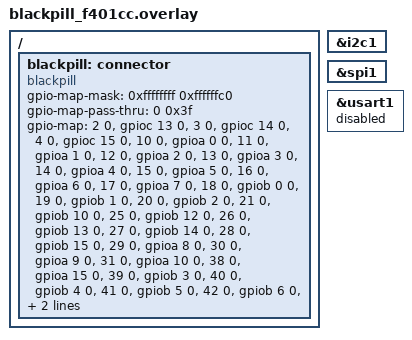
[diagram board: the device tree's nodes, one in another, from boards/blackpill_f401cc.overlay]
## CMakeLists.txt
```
cmake_minimum_required(VERSION 3.13.1)

set(CONFIG_APPLICATION_DEFINED_SYSCALL true)

set(ZEPHYR_BOARD_ALIASES "boards/aliases.cmake")
set(ZEPHYR_EXTRA_MODULES "${ZMK_EXTRA_MODULES};${CMAKE_CURRENT_SOURCE_DIR}/module;${CMAKE_CURRENT_SOURCE_DIR}/keymap-module")

# Find Zephyr. This also loads Zephyr's build system.
find_package(Zephyr REQUIRED HINTS ../zephyr)
project(zmk)

zephyr_linker_sources(SECTIONS include/linker/zmk-behaviors.ld)
zephyr_linker_sources(RODATA include/linker/zmk-events.ld)

if(CONFIG_ZMK_BEHAVIOR_LOCAL_IDS)
  zephyr_linker_sources(DATA_SECTIONS include/linker/zmk-behavior-local-id-map.ld)
endif()

zephyr_syscall_header(${APPLICATION_SOURCE_DIR}/include/drivers/behavior.h)
zephyr_syscall_header(${APPLICATION_SOURCE_DIR}/include/drivers/input_processor.h)
zephyr_syscall_header(${APPLICATION_SOURCE_DIR}/include/drivers/ext_power.h)

# Add your source file to the "app" target. This must come after
# find_package(Zephyr) which defines the target.
target_include_directories(app PRIVATE include)
add_subdirectory(src/boot)
target_sources(app PRIVATE src/stdlib.c)
target_sources(app PRIVATE src/activity.c)
target_sources(app PRIVATE src/behavior.c)
target_sources_ifdef(CONFIG_ZMK_KSCAN_SIDEBAND_BEHAVIORS app PRIVATE src/kscan_sideband_behaviors.c)
target_sources(app PRIVATE src/matrix_transform.c)
target_sources(app PRIVATE src/physical_layouts.c)
target_sources(app PRIVATE src/sensors.c)
target_sources_ifdef(CONFIG_ZMK_WPM app PRIVATE src/wpm.c)
target_sources(app PRIVATE src/event_manager.c)
target_sources_ifdef(CONFIG_ZMK_PM app PRIVATE src/pm.c)
target_sources_ifdef(CONFIG_ZMK_EXT_POWER app PRIVATE src/ext_power_generic.c)
target_sources_ifdef(CONFIG_ZMK_GPIO_KEY_WAKEUP_TRIGGER app PRIVATE src/gpio_key_wakeup_trigger.c)
target_sources(app PRIVATE src/events/activity_state_changed.c)
target_sources(app PRIVATE src/events/position_state_changed.c)
target_sources(app PRIVATE src/events/sensor_event.c)
target_sources_ifdef(CONFIG_ZMK_WPM app PRIVATE src/events/wpm_state_changed.c)
target_sources_ifdef(CONFIG_USB_DEVICE_STACK app PRIVATE src/events/usb_conn_state_changed.c)
target_sources(app PRIVATE src/behaviors/behavior_reset.c)
target_sources_ifdef(CONFIG_ZMK_EXT_POWER app PRIVATE src/behaviors/behavior_ext_power.c)
target_sources_ifdef(CONFIG_ZMK_BEHAVIOR_SOFT_OFF app PRIVATE src/behaviors/behavior_soft_off.c)
add_subdirectory_ifdef(CONFIG_ZMK_POINTING src/pointing/)
if ((NOT CONFIG_ZMK_SPLIT) OR CONFIG_ZMK_SPLIT_ROLE_CENTRAL)
  target_sources(app PRIVATE src/hid.c)
  target_sources(app PRIVATE src/behaviors/behavior_key_press.c)
  target_sources_ifdef(CONFIG_ZMK_BEHAVIOR_KEY_TOGGLE app PRIVATE src/behaviors/behavior_key_toggle.c)
  target_sources_ifdef(CONFIG_ZMK_BEHAVIOR_HOLD_TAP app PRIVATE src/behaviors/behavior_hold_tap.c)
  target_sources_ifdef(CONFIG_ZMK_BEHAVIOR_STICKY_KEY app PRIVATE src/behaviors/behavior_sticky_key.c)
  target_sources(app PRIVATE src/behaviors/behavior_caps_word.c)
  target_sources(app PRIVATE src/behaviors/behavior_key_repeat.c)
  target_sources_ifdef(CONFIG_ZMK_BEHAVIOR_MACRO app PRIVATE src/behaviors/behavior_macro.c)
  target_sources(app PRIVATE src/behaviors/behavior_momentary_layer.c)
  target_sources(app PRIVATE src/behaviors/behavior_mod_morph.c)
  target_sources(app PRIVATE src/behaviors/behavior_outputs.c)
  target_sources(app PRIVATE src/behaviors/behavior_toggle_layer.c)
  target_sources(app PRIVATE src/behaviors/behavior_to_layer.c)
  target_sources(app PRIVATE src/behaviors/behavior_transparent.c)
  target_sources(app PRIVATE src/behaviors/behavior_none.c)
  target_sources_ifdef(CONFIG_ZMK_BEHAVIOR_SENSOR_ROTATE app PRIVATE src/behaviors/behavior_sensor_rotate.c)
  target_sources_ifdef(CONFIG_ZMK_BEHAVIOR_SENSOR_ROTATE_VAR app PRIVATE src/behaviors/behavior_sensor_rotate_var.c)
  target_sources_ifdef(CONFIG_ZMK_BEHAVIOR_SENSOR_ROTATE_COMMON app PRIVATE src/behaviors/behavior_sensor_rotate_common.c)
  target_sources_ifdef(CONFIG_ZMK_BEHAVIOR_MOUSE_KEY_PRESS app PRIVATE src/behaviors/behavior_mouse_key_press.c)
  target_sources_ifdef(CONFIG_ZMK_BEHAVIOR_STUDIO_UNLOCK app PRIVATE src/behaviors/behavior_studio_unlock.c)
  target_sources_ifdef(CONFIG_ZMK_BEHAVIOR_INPUT_TWO_AXIS app PRIVATE src/behaviors/behavior_input_two_axis.c)
  target_sources(app PRIVATE src/combo.c)
  target_sources_ifdef(CONFIG_ZMK_BEHAVIOR_TAP_DANCE app PRIVATE src/behaviors/behavior_tap_dance.c)
  target_sources(app PRIVATE src/behavior_queue.c)
  target_sources(app PRIVATE src/conditional_layer.c)
  target_sources(app PRIVATE src/endpoints.c)
  target_sources(app PRIVATE src/events/endpoint_changed.c)
  target_sources(app PRIVATE src/hid_listener.c)
  target_sources(app PRIVATE src/keymap.c)
  target_sources(app PRIVATE src/events/layer_state_changed.c)
  target_sources(app PRIVATE src/events/modifiers_state_changed.c)
  target_sources(app PRIVATE src/events/keycode_state_changed.c)
  target_sources_ifdef(CONFIG_ZMK_HID_INDICATORS app PRIVATE src/hid_indicators.c)

  if (CONFIG_ZMK_BLE)
    target_sources(app PRIVATE src/events/ble_active_profile_changed.c)
    target_sources(app PRIVATE src/behaviors/behavior_bt.c)
    target_sources(app PRIVATE src/ble.c)
    target_sources(app PRIVATE src/hog.c)
  endif()
endif()

target_sources_ifdef(CONFIG_ZMK_RGB_UNDERGLOW app PRIVATE src/behaviors/behavior_rgb_underglow.c)
target_sources_ifdef(CONFIG_ZMK_BACKLIGHT app PRIVATE src/behaviors/behavior_backlight.c)

if(CONFIG_ZMK_BATTERY_REPORTING)
  target_sources(app PRIVATE src/events/battery_state_changed.c)
  target_sources(app PRIVATE src/battery.c)
  target_sources_ifdef(CONFIG_ZMK_BATTERY_REPORTING_SPLIT_PROXY app PRIVATE src/battery_reporting.c)
endif()

target_sources_ifdef(CONFIG_ZMK_HID_INDICATORS app PRIVATE src/events/hid_indicators_changed.c)
add_subdirectory_ifdef(CONFIG_ZMK_HID_INDICATORS src/indicators)

target_sources_ifdef(CONFIG_ZMK_SPLIT app PRIVATE src/events/split_peripheral_status_changed.c)
add_subdirectory_ifdef(CONFIG_ZMK_SPLIT src/split)

target_sources_ifdef(CONFIG_USB_DEVICE_STACK app PRIVATE src/usb.c)
target_sources_ifdef(CONFIG_ZMK_USB app PRIVATE src/usb_hid.c)
target_sources_ifdef(CONFIG_ZMK_RGB_UNDERGLOW app PRIVATE src/rgb_underglow.c)
target_sources_ifdef(CONFIG_ZMK_BACKLIGHT app PRIVATE src/backlight.c)
target_sources_ifdef(CONFIG_ZMK_LOW_PRIORITY_WORK_QUEUE app PRIVATE src/workqueue.c)
target_sources(app PRIVATE src/main.c)

add_subdirectory(src/display/)
add_subdirectory_ifdef(CONFIG_SETTINGS src/settings/)

if (CONFIG_ZMK_STUDIO_RPC)
  # For some reason this is failing if run from a different sub-file.
  list(APPEND CMAKE_MODULE_PATH ${ZEPHYR_BASE}/modules/nanopb)

  include(nanopb)

    # Turn off the default nanopb behavior
  set(NANOPB_GENERATE_CPP_STANDALONE OFF)

  nanopb_generate_cpp(proto_srcs proto_hdrs RELPATH ${ZEPHYR_ZMK_STUDIO_MESSAGES_MODULE_DIR}
                        ${ZEPHYR_ZMK_STUDIO_MESSAGES_MODULE_DIR}/proto/zmk/studio.proto
                        ${ZEPHYR_ZMK_STUDIO_MESSAGES_MODULE_DIR}/proto/zmk/meta.proto
                        ${ZEPHYR_ZMK_STUDIO_MESSAGES_MODULE_DIR}/proto/zmk/core.proto
                        ${ZEPHYR_ZMK_STUDIO_MESSAGES_MODULE_DIR}/proto/zmk/behaviors.proto
                        ${ZEPHYR_ZMK_STUDIO_MESSAGES_MODULE_DIR}/proto/zmk/keymap.proto
  )

  target_include_directories(app PUBLIC ${CMAKE_CURRENT_BINARY_DIR})
  target_sources(app PRIVATE ${proto_srcs} ${proto_hdrs})

  add_subdirectory(src/studio)
endif()

zephyr_cc_option(-Wfatal-errors)
```

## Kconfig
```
# Copyright (c) 2020 The ZMK Contributors
# SPDX-License-Identifier: MIT

mainmenu "ZMK Firmware"

menu "ZMK"

config ZMK_BOARD_COMPAT
    bool
    help
      Hidden symbol used to hint that a board has been specifically
      set up with various ZMK requirements in mind, e.g. settings
      storage, bootloader integration, etc.

      Failure to set this will warn users they may want to verify they
      used a ZMK variant of an upstream board, or are using a board
      properly migrated to a newer ZMK version.

menu "Basic Keyboard Setup"

config ZMK_KEYBOARD_NAME
    string "Keyboard Name"

config USB_DEVICE_PRODUCT
    default ZMK_KEYBOARD_NAME

config BT_DEVICE_NAME
    default ZMK_KEYBOARD_NAME

config USB_DEVICE_VID
    default 0x1D50

config USB_DEVICE_PID
    default 0x615E

config USB_DEVICE_MANUFACTURER
    default "ZMK Project"

config BT_DIS_PNP_VID
    default 0x1D50

config BT_DIS_PNP_PID
    default 0x615E

config BT_DIS_PNP_VID_SRC
    default 2

config BT_DIS_MODEL_NUMBER_STR
    default ZMK_KEYBOARD_NAME

config BT_DIS_MANUF_NAME_STR
    default "ZMK Project"

# Hardware specific overrides

if SOC_SERIES_NRF52X

# Default on for our usage until boards implement retained bootmode.
config NRF_STORE_REBOOT_TYPE_GPREGRET
    bool
    default y

endif # SOC_SERIES_NRF52X

menu "HID"

choice ZMK_HID_REPORT_TYPE
    prompt "HID Report Type"

config ZMK_HID_REPORT_TYPE_HKRO
    bool "#-Key Roll Over (HKRO) HID Report"
    help
      Enable # key roll over for HID report. This selection is "boot keyboard" compatible
      but limits the total number of possible keys to report as held to #.

config ZMK_HID_REPORT_TYPE_NKRO
    bool "Full N-Key Roll Over (NKRO) HID Report"
    help
      Enable full N-Key Roll Over for HID output. This selection will prevent the keyboard
      from working with some BIOS/UEFI versions that only support "boot keyboard" support.
      This option also prevents using some infrequently used higher range HID usages (notably F13-F24 and INTL1-9)
      These usages can be re enabled with ZMK_HID_KEYBOARD_NKRO_EXTENDED_REPORT.

endchoice

config ZMK_HID_KEYBOARD_NKRO_EXTENDED_REPORT
    bool "Enable extended NKRO reporting"
    depends on ZMK_HID_REPORT_TYPE_NKRO
    help
      Enables higher usage range for NKRO (F13-F24 and INTL1-9).
      Please note this is not compatible with Android currently and you will get no input


if ZMK_HID_REPORT_TYPE_HKRO

config ZMK_HID_KEYBOARD_REPORT_SIZE
    int "# Keyboard Keys Reportable"

endif # ZMK_HID_REPORT_TYPE_HKRO

config ZMK_HID_CONSUMER_REPORT_SIZE
    int "# Consumer Keys Reportable"

choice ZMK_HID_CONSUMER_REPORT_USAGES
    prompt "HID Report Type"

config ZMK_HID_CONSUMER_REPORT_USAGES_FULL
    bool "Full Consumer HID Usage Support"
    help
      Enable full Consumer usage ID values to be sent to hosts. Allows for less
      frequently used usages, but has compatibability issues with some host OSes.

config ZMK_HID_CONSUMER_REPORT_USAGES_BASIC
    bool "Basic Consumer HID Usage Support"
    help
      Enable Consumer usage ID values up to "Playback Speed - Slow" to be sent to
      hosts. Allows for broader compatibability with more host OSes.

endchoice

config ZMK_HID_INDICATORS
    bool "HID Indicators"
    help
      Enable HID indicators, used for detecting state of Caps/Scroll/Num Lock,
      Kata, and Compose.

rsource "src/indicators/Kconfig"

config ZMK_HID_SEPARATE_MOD_RELEASE_REPORT
    bool "Release Modifiers Separately"
    help
      Send a separate release event for the modifiers, to make sure the release
      of the modifier doesn't get recognized before the actual key's release event.

menu "Output Types"

config ZMK_USB
    bool "USB"
    depends on (!ZMK_SPLIT || (ZMK_SPLIT && ZMK_SPLIT_ROLE_CENTRAL))
    select USB
    select USB_DEVICE_STACK
    select USB_DEVICE_HID

config ZMK_USB_BOOT
    bool "USB Boot Protocol Support"
    depends on ZMK_USB
    select USB_HID_BOOT_PROTOCOL

config USB_DEVICE_INITIALIZE_AT_BOOT
    default n

if ZMK_USB

config USB_NUMOF_EP_WRITE_RETRIES
    default 10

config USB_HID_POLL_INTERVAL_MS
    default 1

endif # ZMK_USB

menuconfig ZMK_BLE
    bool "BLE (HID over GATT)"
    select BT
    select BT_SMP
    select BT_SMP_SC_PAIR_ONLY
    select BT_SMP_APP_PAIRING_ACCEPT
    select BT_PERIPHERAL
    select BT_DIS
    imply BT_DEVICE_NAME_DYNAMIC
    imply BT_SETTINGS if !ARCH_POSIX
    imply SETTINGS if !ARCH_POSIX
    imply ZMK_BATTERY_REPORTING if !ARCH_POSIX

if ZMK_BLE

config ZMK_BLE_EXPERIMENTAL_CONN
    bool "Experimental BLE connection changes"
    help
      Enables settings that are planned to be default in future versions of ZMK
      to improve connection stability.

config ZMK_BLE_EXPERIMENTAL_SEC
    bool "Experimental BLE security changes"
    imply BT_SMP_ALLOW_UNAUTH_OVERWRITE
    help
      Enables security settings that are planned to be officially supported in the future.

config ZMK_BLE_EXPERIMENTAL_FEATURES
    bool "Experimental BLE connection and security settings/features"
    select ZMK_BLE_EXPERIMENTAL_CONN
    select ZMK_BLE_EXPERIMENTAL_SEC
    help
      Enables experimental connection changes and security features.

config ZMK_BLE_PASSKEY_ENTRY
    bool "Require passkey entry on the keyboard to complete pairing"
    select RING_BUFFER

config BT_SMP_ALLOW_UNAUTH_OVERWRITE
    imply ZMK_BLE_PASSKEY_ENTRY

config BT_CTLR_PHY_2M
    default n if ZMK_BLE_EXPERIMENTAL_CONN

config ZMK_BLE_THREAD_STACK_SIZE
    int "BLE notify thread stack size"
    default 768

config ZMK_BLE_THREAD_PRIORITY
    int "BLE notify thread priority"
    default 5

config ZMK_BLE_KEYBOARD_REPORT_QUEUE_SIZE
    int "Max number of keyboard HID reports to queue for sending over BLE"
    default 20

config ZMK_BLE_CONSUMER_REPORT_QUEUE_SIZE
    int "Max number of consumer HID reports to queue for sending over BLE"
    default 5

config ZMK_BLE_MOUSE_REPORT_QUEUE_SIZE
    int "Max number of mouse HID reports to queue for sending over BLE"
    default 20

config ZMK_BLE_CLEAR_BONDS_ON_START
    bool "Configuration that clears all bond information from the keyboard on startup."

# HID GATT notifications sent this way are *not* picked up by Linux, and possibly others.
config BT_GATT_NOTIFY_MULTIPLE
    default n

config BT_GATT_AUTO_SEC_REQ
    default (ZMK_SPLIT_BLE && !ZMK_SPLIT_ROLE_CENTRAL)

config BT_PERIPHERAL_PREF_MIN_INT
    default 6

config BT_PERIPHERAL_PREF_MAX_INT
    default 12

config BT_PERIPHERAL_PREF_LATENCY
    default 30

config BT_PERIPHERAL_PREF_TIMEOUT
    default 400

# The device name should be 16 characters or less so it fits within the
# advertising data.
config BT_DEVICE_NAME_MAX
    default 16

endif # ZMK_BLE

endmenu # Output Types

endmenu # HID

rsource "src/split/Kconfig"

endmenu # Basic Keyboard Setup

menu "Keymaps"

config ZMK_KEYMAP_LAYER_REORDERING
    bool "Layer Reordering Support"

config ZMK_KEYMAP_SETTINGS_STORAGE
    bool "Settings Save/Load"
    depends on SETTINGS
    depends on ZMK_BEHAVIOR_LOCAL_IDS

if ZMK_KEYMAP_SETTINGS_STORAGE

config ZMK_KEYMAP_LAYER_NAME_MAX_LEN
    int "Max Layer Name Length"
    default 20

endif # ZMK_KEYMAP_SETTINGS_STORAGE

endmenu # Keymaps

rsource "src/studio/Kconfig"

menu "Display/LED Options"

rsource "src/display/Kconfig"

menuconfig ZMK_RGB_UNDERGLOW
    bool "RGB Addressable LED Underglow"
    select LED_STRIP
    select ZMK_LOW_PRIORITY_WORK_QUEUE

if ZMK_RGB_UNDERGLOW

config ZMK_RGB_UNDERGLOW_EXT_POWER
    bool "RGB underglow toggling also controls external power"

config ZMK_RGB_UNDERGLOW_BRT_MIN
    int "RGB underglow minimum brightness in percent"
    range 0 100

config ZMK_RGB_UNDERGLOW_BRT_MAX
    int "RGB underglow maximum brightness in percent"
    range ZMK_RGB_UNDERGLOW_BRT_MIN 100

config ZMK_RGB_UNDERGLOW_HUE_STEP
    int "RGB underglow hue step in degrees"
    range 0 359

config ZMK_RGB_UNDERGLOW_SAT_STEP
    int "RGB underglow saturation step in percent"
    range 0 100

config ZMK_RGB_UNDERGLOW_BRT_STEP
    int "RGB underglow brightness step in percent"
    range 0 100

config ZMK_RGB_UNDERGLOW_HUE_START
    int "RGB underglow start hue value in degrees"
    range 0 359

config ZMK_RGB_UNDERGLOW_SAT_START
    int "RGB underglow start saturations value in percent"
    range 0 100

config ZMK_RGB_UNDERGLOW_BRT_START
    int "RGB underglow start brightness value in percent"
    range ZMK_RGB_UNDERGLOW_BRT_MIN ZMK_RGB_UNDERGLOW_BRT_MAX

config ZMK_RGB_UNDERGLOW_SPD_START
    int "RGB underglow start animation speed value"
    range 1 5

config ZMK_RGB_UNDERGLOW_EFF_START
    int "RGB underglow start effect int value related to the effect enum list"
    range 0 3

config ZMK_RGB_UNDERGLOW_ON_START
    bool "RGB underglow starts on by default"

config ZMK_RGB_UNDERGLOW_AUTO_OFF_IDLE
    bool "Turn off RGB underglow when keyboard goes into idle state"

config ZMK_RGB_UNDERGLOW_AUTO_OFF_USB
    bool "Turn off RGB underglow when USB is disconnected"
    depends on USB_DEVICE_STACK

endif # ZMK_RGB_UNDERGLOW

menuconfig ZMK_BACKLIGHT
    bool "LED backlight"
    select LED

if ZMK_BACKLIGHT

config ZMK_BACKLIGHT_BRT_STEP
    int "Brightness step in percent"
    range 1 100

config ZMK_BACKLIGHT_BRT_START
    int "Default brightness in percent"
    range 1 100

config ZMK_BACKLIGHT_ON_START
    bool "Default backlight state"

config ZMK_BACKLIGHT_AUTO_OFF_IDLE
    bool "Turn off backlight when keyboard goes into idle state"

config ZMK_BACKLIGHT_AUTO_OFF_USB
    bool "Turn off backlight when USB is disconnected"

endif # ZMK_BACKLIGHT

endmenu # Display/LED Options

rsource "src/pointing/Kconfig"

menu "Power Management"

config ZMK_BATTERY_REPORTING
    bool "Battery level detection/reporting"
    select SENSOR
    select ZMK_LOW_PRIORITY_WORK_QUEUE

if ZMK_BATTERY_REPORTING

choice ZMK_BATTERY_REPORTING_FETCH_MODE
    prompt "Battery Reporting Fetch Mode"

config ZMK_BATTERY_REPORTING_FETCH_MODE_STATE_OF_CHARGE
    bool "State of charge"

config ZMK_BATTERY_REPORTING_FETCH_MODE_LITHIUM_VOLTAGE
    bool "Lithium Voltage"

endchoice

config ZMK_BATTERY_REPORTING_BLE
    bool "Report Battery Level over BLE Battery Service"
    default y
    depends on ZMK_BLE
    select BT_BAS if (!ZMK_SPLIT || (ZMK_SPLIT && !ZMK_SPLIT_ROLE_CENTRAL))

config ZMK_BATTERY_REPORTING_USB
    bool "Report Battery Level over USB HID"
    depends on ZMK_USB

config ZMK_BATTERY_CHARGE_STATUS
    bool "Report whether the battery is charging"
    default y
    depends on DT_HAS_ZMK_BATTERY_CHARGE_STATUS_ENABLED
    select BT_BAS_BLS if BT_BAS
    help
      Reads the status output of the board's battery charger to report whether
      the battery is charging, using the zmk,battery-charge-status devicetree
      node. Without such a node there is no way to know, and the charge state
      is reported as unknown.

if ZMK_SPLIT_ROLE_CENTRAL

config ZMK_BATTERY_REPORTING_SPLIT_FETCHING
    bool "Fetch Peripheral Battery Level Info"
    help
      Adds internal support for fetching the battery levels from peripherals
      and generating events in the ZMK eventing system.

config ZMK_BATTERY_PROXY
    bool "Proxy Battery Level Info"
    default y if ZMK_SPLIT_BLE_CENTRAL_BATTERY_LEVEL_PROXY
    help
      Adds support for reporting the battery levels of connected split
      peripherals through additional Battery Level services.

config ZMK_BATTERY_PROXY_REPORT_LOWEST_CHARGE
    bool "Report the lowest charge of all batteries"
    depends on ZMK_BATTERY_PROXY
    default y
    help
      Report the lowest charge as the first battery level to hosts.

endif # ZMK_SPLIT_ROLE_CENTRAL

endif # ZMK_BATTERY_REPORTING

config ZMK_IDLE_TIMEOUT
    int "Milliseconds of inactivity before entering idle state (OLED shutoff, etc)"
    default 30000

config ZMK_SLEEP
    bool "Enable deep sleep support"
    depends on HAS_POWEROFF
    select POWEROFF
    select ZMK_PM_DEVICE_SUSPEND_RESUME
    imply USB

if ZMK_SLEEP

config PM_DEVICE
    default y

config ZMK_IDLE_SLEEP_TIMEOUT
    int "Milliseconds of inactivity before entering deep sleep"
    default 900000

endif # ZMK_SLEEP

config ZMK_EXT_POWER
    bool "Enable support to control external power output"

config ZMK_PM
    bool

config ZMK_PM_DEVICE_SUSPEND_RESUME
    bool
    select ZMK_PM

config ZMK_PM_SOFT_OFF
    bool "Soft-off support"
    depends on HAS_POWEROFF
    select ZMK_PM
    select PM_DEVICE
    select ZMK_PM_DEVICE_SUSPEND_RESUME
    select POWEROFF

config ZMK_GPIO_KEY_WAKEUP_TRIGGER
    bool "Hardware supported wakeup (GPIO)"
    default y
    depends on DT_HAS_ZMK_GPIO_KEY_WAKEUP_TRIGGER_ENABLED && ZMK_PM_SOFT_OFF

# Power Management
endmenu

menu "Combo options"

config ZMK_COMBO_MAX_PRESSED_COMBOS
    int "Maximum number of currently pressed combos"
    default 4

config ZMK_COMBO_MAX_COMBOS_PER_KEY
    int "Deprecated: Max combos per key"
    default 0
    help
      Deprecated: Storage for combos is now determined automatically

config ZMK_COMBO_MAX_KEYS_PER_COMBO
    int "Deprecated: Max keys per combo"
    default 0
    help
       Deprecated: This is now auto-calculated based on `key-positions` in devicetree

# Combo options
endmenu

menu "Behavior Options"

config ZMK_BEHAVIORS_QUEUE_SIZE
    int "Maximum number of behaviors to allow queueing from a macro or other complex behavior"
    default 64

rsource "Kconfig.behaviors"

config ZMK_MACRO_DEFAULT_WAIT_MS
    int "Default time to wait (in milliseconds) before triggering the next behavior in macros"
    default 15

config ZMK_MACRO_DEFAULT_TAP_MS
    int "Default time to wait (in milliseconds) between the press and release events of a tapped behavior in macros"
    default 30

endmenu

menu "Advanced"

rsource "src/boot/Kconfig"

menu "Initialization Priorities"

if USB_DEVICE_STACK

config ZMK_USB_INIT_PRIORITY
    int "USB Init Priority"
    default 96

config ZMK_USB_HID_INIT_PRIORITY
    int "USB HID Init Priority"
    default 95

endif # USB

if ZMK_BLE || ZMK_SPLIT_BLE

config ZMK_BLE_INIT_PRIORITY
    int "BLE Init Priority"
    default 50

endif # ZMK_BLE || ZMK_SPLIT_BLE

endmenu # Initialization Priorities

config ZMK_PHYSICAL_LAYOUT_KEY_ROTATION
    bool "Support rotation of keys in physical layouts"
    default y

menuconfig ZMK_KSCAN
    bool "ZMK KScan Integration"
    default y
    select KSCAN

if ZMK_KSCAN

config ZMK_KSCAN_EVENT_QUEUE_SIZE
    int "Size of the event queue for KSCAN events to buffer events"
    default 4

endif # ZMK_KSCAN

config ZMK_KSCAN_SIDEBAND_BEHAVIORS
    bool
    default y
    depends on DT_HAS_ZMK_KSCAN_SIDEBAND_BEHAVIORS_ENABLED
    select KSCAN

if ZMK_KSCAN_SIDEBAND_BEHAVIORS

config ZMK_KSCAN_SIDEBAND_BEHAVIORS_INIT_PRIORITY
    int "Keyboard scan sideband behaviors driver init priority"
    # The default kscan init priority is 90, so be sure we are initialized later.
    default 95

endif # ZMK_KSCAN_SIDEBAND_BEHAVIORS

menu "Logging"

config ZMK_LOGGING_MINIMAL
    bool "Suppress all ZMK debug log messages"
    default false

if !ZMK_LOGGING_MINIMAL

config ZMK_LOG_LEVEL
    default 4

endif

config ZMK_USB_LOGGING
    bool "Enable USB CDC ACM logging to help debug"
    select LOG
    select USB
    select USB_DEVICE_STACK
    select USB_CDC_ACM
    select SERIAL
    select CONSOLE
    select UART_INTERRUPT_DRIVEN
    select UART_LINE_CTRL
    select UART_CONSOLE
    select USB_UART_CONSOLE

if ZMK_USB_LOGGING

choice USB_CDC_ACM_LOG_LEVEL_CHOICE
    default USB_CDC_ACM_LOG_LEVEL_OFF
endchoice

choice USB_DRIVER_LOG_LEVEL_CHOICE
    default USB_DRIVER_LOG_LEVEL_OFF
endchoice

# We do this to avoid log loop where logging to USB generates more log messages.

config USB_CDC_ACM_RINGBUF_SIZE
    default 1024

config LOG_PROCESS_THREAD_STARTUP_DELAY_MS
    default 1000

endif # ZMK_USB_LOGGING

config ZMK_RTT_LOGGING
    bool "Enable RTT logging to help debug"
    select LOG
    select DEBUG
    select ASSERT
    select USE_SEGGER_RTT
    select CONSOLE
    select RTT_CONSOLE

if ZMK_RTT_LOGGING

config SEGGER_RTT_BUFFER_SIZE_UP
    default 8192

endif # ZMK_RTT_LOGGING

if ZMK_USB_LOGGING || ZMK_RTT_LOGGING

config LOG_BUFFER_SIZE
    default 8192

config LOG_PROCESS_THREAD_SLEEP_MS
    default 100

endif # ZMK_USB_LOGGING || ZMK_RTT_LOGGING

endmenu # Logging

if SETTINGS

config ZMK_SETTINGS_RESET_ON_START
    bool "Delete all persistent settings when the keyboard boots"

if ZMK_SETTINGS_RESET_ON_START

config ZMK_SETTINGS_RESET_ON_START_INIT_PRIORITY
    int "Settings Reset ON Start Initialization Priority"
    default 60
    help
      Initialization priority for the settings reset on start. Must be lower priority/
      higher value than FLASH_INIT_PRIORITY if using the NVS/Flash settings backend.

endif # ZMK_SETTINGS_RESET_ON_START

config ZMK_SETTINGS_SAVE_DEBOUNCE
    int "Milliseconds to debounce settings saves"
    default 60000

endif # SETTINGS

config ZMK_BATTERY_REPORT_INTERVAL
    depends on ZMK_BATTERY_REPORTING
    int "Battery level report interval in seconds"

config ZMK_LOW_PRIORITY_WORK_QUEUE
    bool "Work queue for low priority items"

if ZMK_LOW_PRIORITY_WORK_QUEUE

config ZMK_LOW_PRIORITY_THREAD_STACK_SIZE
    int "Low priority thread stack size"
    default 768

config ZMK_LOW_PRIORITY_THREAD_PRIORITY
    int "Low priority thread priority"
    default 10

endif # ZMK_LOW_PRIORITY_WORK_QUEUE

endmenu # Advanced

endmenu # ZMK

if SOC_FAMILY_NORDIC_NRF

config NRF_SOC_VALIDATE_HEADERS_DISABLED
    default y

endif

config KERNEL_BIN_NAME
    default "zmk"

config REBOOT
    default y

config USB_DEVICE_STACK
    default y if HAS_HW_NRF_USBD

config FPU
    default CPU_HAS_FPU

config ZMK_WPM
    bool "Calculate WPM"

config ZMK_KEYMAP_SENSORS
    bool "Enable Keymap Sensors support"
    default y
    depends on DT_HAS_ZMK_KEYMAP_SENSORS_ENABLED
    select SENSOR

if ZMK_KEYMAP_SENSORS

config ZMK_KEYMAP_SENSORS_DEFAULT_TRIGGERS_PER_ROTATION
    int "Default triggers per rotation"
    help
      Unless overridden for a sensor in the board/shield/devicetree, this value
      determines how many times to trigger the bound behavior per full rotation.
      For tactile encoders with detents, this usually should match the number of
      detents per rotation of the encoder.
    default 20

endif # ZMK_KEYMAP_SENSORS

module = ZMK
module-str = zmk
source "subsys/logging/Kconfig.template.log_config"

# This loads ZMK's internal board and shield Kconfigs
rsource "boards/Kconfig"
rsource "boards/shields/*/Kconfig.defconfig"
rsource "boards/shields/*/Kconfig.shield"

# This loads custom shields defconfigs (from BOARD_ROOT)
# Duplicated from Kconfig.zephyr
osource "$(KCONFIG_BINARY_DIR)/Kconfig.shield.defconfig"

# This loads board and shield Kconfigs found under zmk-config/config/
osource "$(ZMK_CONFIG)/boards/shields/*/Kconfig.defconfig"
osource "$(ZMK_CONFIG)/boards/shields/*/Kconfig.shield"

# This loads ZMK's sensible defaults
rsource "Kconfig.defaults"

source "Kconfig.zephyr"
```

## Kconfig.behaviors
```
# Copyright (c) 2023 The ZMK Contributors
# SPDX-License-Identifier: MIT

config ZMK_BEHAVIOR_METADATA
    bool "Metadata"
    help
      Enabling this option adds APIs for documenting and fetching
      metadata describing a behaviors name, and supported parameters.

config ZMK_BEHAVIOR_LOCAL_IDS
    bool "Local IDs"

if ZMK_BEHAVIOR_LOCAL_IDS

config ZMK_BEHAVIOR_LOCAL_IDS_IN_BINDINGS
    bool "Track in behavior bindings"

choice ZMK_BEHAVIOR_LOCAL_ID_TYPE
    prompt "Local ID Type"

config ZMK_BEHAVIOR_LOCAL_ID_TYPE_SETTINGS_TABLE
    bool "Settings Table"
    depends on SETTINGS
    select ZMK_BEHAVIOR_LOCAL_IDS_IN_BINDINGS
    help
      Use persistent entries in the settings subsystem to identify
      behaviors by local ID, which uses the device name to generate
      a new settings entry tying a presistant local ID to that name.
      This guarantees stable, colllision-free local IDs at the expense
      of settings storage used.

config ZMK_BEHAVIOR_LOCAL_ID_TYPE_CRC16
    bool "CRC16 Hash"
    select CRC
    help
      Use the CRC16-ANSI hash of behavior device names to generate
      stable behavior local IDs. This saves on settings storage at
      the expense of (highly unlikely) risk of collisions.

endchoice

endif


config ZMK_BEHAVIOR_HOLD_TAP
    bool
    default y
    depends on DT_HAS_ZMK_BEHAVIOR_HOLD_TAP_ENABLED

if ZMK_BEHAVIOR_HOLD_TAP

config ZMK_BEHAVIOR_HOLD_TAP_MAX_HELD
    int "Hold Tap Max Held"
    help
      Max number of simultaneously held hold-taps

config ZMK_BEHAVIOR_HOLD_TAP_MAX_CAPTURED_EVENTS
    int "Hold Tap Max Captured Events"
    help
      Max number of captured system events while waiting to resolve hold taps

endif

config ZMK_BEHAVIOR_KEY_TOGGLE
    bool
    default y
    depends on DT_HAS_ZMK_BEHAVIOR_KEY_TOGGLE_ENABLED

config ZMK_BEHAVIOR_MOUSE_KEY_PRESS
    bool
    default y
    depends on DT_HAS_ZMK_BEHAVIOR_MOUSE_KEY_PRESS_ENABLED && ZMK_POINTING

config ZMK_BEHAVIOR_STICKY_KEY
    bool
    default y
    depends on DT_HAS_ZMK_BEHAVIOR_STICKY_KEY_ENABLED

if ZMK_BEHAVIOR_STICKY_KEY

config ZMK_BEHAVIOR_STICKY_KEY_MAX_HELD
    int "Sticky Key Max Held"
    help
      Max number of simultaneously held sticky keys

endif

config ZMK_BEHAVIOR_SOFT_OFF
    bool
    default y
    depends on DT_HAS_ZMK_BEHAVIOR_SOFT_OFF_ENABLED && ZMK_PM_SOFT_OFF


config ZMK_BEHAVIOR_TAP_DANCE
    bool
    default y
    depends on DT_HAS_ZMK_BEHAVIOR_TAP_DANCE_ENABLED

if ZMK_BEHAVIOR_TAP_DANCE

config ZMK_BEHAVIOR_TAP_DANCE_MAX_HELD
    int "Tap-Dance Max Held"
    help
      Max number of simultaneously held taps-dances

endif

config ZMK_BEHAVIOR_INPUT_TWO_AXIS
    bool
    default y
    depends on DT_HAS_ZMK_BEHAVIOR_INPUT_TWO_AXIS_ENABLED && ZMK_POINTING

config ZMK_BEHAVIOR_SENSOR_ROTATE_COMMON
    bool

config ZMK_BEHAVIOR_SENSOR_ROTATE
    bool
    default y
    depends on DT_HAS_ZMK_BEHAVIOR_SENSOR_ROTATE_ENABLED
    select ZMK_BEHAVIOR_SENSOR_ROTATE_COMMON

config ZMK_BEHAVIOR_SENSOR_ROTATE_VAR
    bool
    default y
    depends on DT_HAS_ZMK_BEHAVIOR_SENSOR_ROTATE_VAR_ENABLED
    select ZMK_BEHAVIOR_SENSOR_ROTATE_COMMON

config ZMK_BEHAVIOR_STUDIO_UNLOCK
    bool
    default y
    depends on DT_HAS_ZMK_BEHAVIOR_STUDIO_UNLOCK_ENABLED && ZMK_STUDIO

config ZMK_BEHAVIOR_MACRO
    bool
    default y
    depends on DT_HAS_ZMK_BEHAVIOR_MACRO_ENABLED || DT_HAS_ZMK_BEHAVIOR_MACRO_ONE_PARAM_ENABLED || DT_HAS_ZMK_BEHAVIOR_MACRO_TWO_PARAM_ENABLED

config ZMK_BEHAVIOR_TRI_STATE
    bool
    default y
    depends on DT_HAS_ZMK_BEHAVIOR_TRI_STATE_ENABLED
```

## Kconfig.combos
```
# Copyright (c) 2020 The ZMK Contributors
# SPDX-License-Identifier: MIT

menuconfig ZMK_COMBOS
    bool "Combos"
    default y
    depends on DT_HAS_ZMK_COMBOS_ENABLED

if ZMK_COMBOS

config ZMK_COMBO_MAX_PRESSED_COMBOS
    int "Maximum number of currently pressed combos"
    default 4

config ZMK_COMBO_MAX_COMBOS_PER_KEY
    int "Deprecated: Max combos per key"
    default 0
    help
      Deprecated: Storage for combos is now determined automatically

config ZMK_COMBO_MAX_KEYS_PER_COMBO
    int "Deprecated: Max keys per combo"
    default 0
    help
       Deprecated: This is now auto-calculated based on `key-positions` in devicetree

config ZMK_COMBOS_RUNTIME
    bool "Runtime combo updates"

if ZMK_COMBOS_RUNTIME

config ZMK_COMBOS_RUNTIME_SETTINGS_STORAGE
    bool "Save/restore runtime combos using settings"
    default y
    depends on SETTINGS

config ZMK_COMBOS_RUNTIME_SHELL_CMD
    bool "Combos shell command"
    default y
    depends on SHELL

endif

endif
```

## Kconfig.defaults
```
# Copyright (c) 2024 The ZMK Contributors
# SPDX-License-Identifier: MIT

config SYSTEM_WORKQUEUE_STACK_SIZE
    default 3072 if ZMK_DISPLAY
    default 2048

# Basic
config BT_DEVICE_APPEARANCE
    default 961

# HID
if ZMK_HID_REPORT_TYPE_HKRO

config ZMK_HID_KEYBOARD_REPORT_SIZE
    default 6

endif

config ZMK_HID_CONSUMER_REPORT_SIZE
    default 6

# Behaviors

if ZMK_BEHAVIOR_HOLD_TAP

config ZMK_BEHAVIOR_HOLD_TAP_MAX_HELD
    default 10

config ZMK_BEHAVIOR_HOLD_TAP_MAX_CAPTURED_EVENTS
    default 40

endif

if ZMK_BEHAVIOR_STICKY_KEY

config ZMK_BEHAVIOR_STICKY_KEY_MAX_HELD
    default 10

endif

if ZMK_BEHAVIOR_TAP_DANCE

config ZMK_BEHAVIOR_TAP_DANCE_MAX_HELD
    default 10

endif

# Underglow
if ZMK_RGB_UNDERGLOW

# This default value cuts down on tons of excess .conf files, if you're using GPIO, manually disable this
config SPI
    default y

config ZMK_RGB_UNDERGLOW_EXT_POWER
    default y

config ZMK_RGB_UNDERGLOW_BRT_MIN
    default 0

config ZMK_RGB_UNDERGLOW_BRT_MAX
    default 100

config ZMK_RGB_UNDERGLOW_HUE_STEP
    default 10

config ZMK_RGB_UNDERGLOW_SAT_STEP
    default 10

config ZMK_RGB_UNDERGLOW_BRT_STEP
    default 10

config ZMK_RGB_UNDERGLOW_HUE_START
    default 0

config ZMK_RGB_UNDERGLOW_SAT_START
    default 100

config ZMK_RGB_UNDERGLOW_BRT_START
    default ZMK_RGB_UNDERGLOW_BRT_MAX

config ZMK_RGB_UNDERGLOW_SPD_START
    default 3

config ZMK_RGB_UNDERGLOW_EFF_START
    default 0

config ZMK_RGB_UNDERGLOW_ON_START
    default y

endif # ZMK_RGB_UNDERGLOW

# Backlight
if ZMK_BACKLIGHT

config ZMK_BACKLIGHT_BRT_STEP
    default 20

config ZMK_BACKLIGHT_BRT_START
    default 40

config ZMK_BACKLIGHT_ON_START
    default y

endif # ZMK_BACKLIGHT

# LED matrix
if ZMK_LED_MATRIX

config ZMK_LED_MATRIX_BRT_STEP
    default 10

config ZMK_LED_MATRIX_BRT_START
    default 60

config ZMK_LED_MATRIX_PROFILE_START
    default 0

config ZMK_LED_MATRIX_SPD_LEVELS
    default 7

config ZMK_LED_MATRIX_SPD_START
    default 4 if ZMK_LED_MATRIX_SPD_LEVELS >= 4
    default ZMK_LED_MATRIX_SPD_LEVELS

config ZMK_LED_MATRIX_ON_START
    default y

config ZMK_LED_MATRIX_IDLE_STATUS_WAKE_TIMEOUT
    default 1800000

endif # ZMK_LED_MATRIX

# Ext_power
config ZMK_EXT_POWER
    default y

# Battery
config ZMK_BATTERY_REPORT_INTERVAL
    default 60

# Imports
rsource "src/boot/Kconfig.defaults"
rsource "src/split/Kconfig.defaults"
```

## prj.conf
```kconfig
CONFIG_APPLICATION_DEFINED_SYSCALL=y

CONFIG_BT_SMP_SC_PAIR_ONLY=n
```

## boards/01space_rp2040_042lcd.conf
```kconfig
CONFIG_ZMK_DISPLAY=y
CONFIG_LV_FONT_UNSCII_8=n
CONFIG_ZMK_USB=y
CONFIG_I2C=y
CONFIG_I2C_DW=y
CONFIG_LV_Z_VDB_SIZE=50
```

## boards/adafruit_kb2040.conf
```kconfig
CONFIG_CONSOLE=n
CONFIG_SERIAL=n
CONFIG_UART_CONSOLE=n
CONFIG_ZMK_USB=y

CONFIG_RETAINED_MEM=y
CONFIG_RETENTION=y
CONFIG_RETENTION_BOOT_MODE=y
```

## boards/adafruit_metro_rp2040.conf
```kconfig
CONFIG_CONSOLE=n
CONFIG_SERIAL=n
CONFIG_UART_CONSOLE=n
CONFIG_ZMK_USB=y

CONFIG_MPU_ALLOW_FLASH_WRITE=y
CONFIG_NVS=y
CONFIG_SETTINGS_NVS=y
CONFIG_FLASH=y
CONFIG_FLASH_PAGE_LAYOUT=y
CONFIG_FLASH_MAP=y
```

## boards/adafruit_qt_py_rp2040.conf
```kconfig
CONFIG_CONSOLE=n
CONFIG_SERIAL=n
CONFIG_UART_CONSOLE=n
CONFIG_ZMK_USB=y

CONFIG_RETAINED_MEM=y
CONFIG_RETENTION=y
CONFIG_RETENTION_BOOT_MODE=y
```

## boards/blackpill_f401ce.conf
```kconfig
CONFIG_CONSOLE=n
CONFIG_SERIAL=n
CONFIG_UART_CONSOLE=n
CONFIG_UART_INTERRUPT_DRIVEN=n
CONFIG_ZMK_USB=y
CONFIG_ZMK_KSCAN_MATRIX_POLLING=y
```

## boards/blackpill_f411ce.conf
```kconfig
CONFIG_CONSOLE=n
CONFIG_SERIAL=n
CONFIG_UART_CONSOLE=n
CONFIG_UART_INTERRUPT_DRIVEN=n
CONFIG_ZMK_USB=y
CONFIG_ZMK_BLE=n
CONFIG_ZMK_KSCAN_MATRIX_POLLING=y
```

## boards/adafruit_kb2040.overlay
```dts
/*
 * Copyright (c) 2023 The ZMK Contributors
 *
 * SPDX-License-Identifier: MIT
 */

#include <common/rp2-boot-mode-retention.dtsi>

&pro_micro_serial { status = "disabled"; };
```

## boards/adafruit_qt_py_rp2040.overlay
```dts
/*
 * Copyright (c) 2023 The ZMK Contributors
 *
 * SPDX-License-Identifier: MIT
 */

#include <common/rp2-boot-mode-retention.dtsi>

&xiao_serial { status = "disabled"; };
```

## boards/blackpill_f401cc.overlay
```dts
/*
 * Copyright (c) 2024 The ZMK Contributors
 *
 * SPDX-License-Identifier: MIT
 */

/ {
    blackpill: connector {
        compatible = "blackpill";
        #gpio-cells = <2>;
        gpio-map-mask = <0xffffffff 0xffffffc0>;
        gpio-map-pass-thru = <0 0x3f>;
        gpio-map
            = <2  0 &gpioc 13 0>    /* PC13 */
            , <3  0 &gpioc 14 0>    /* PC14 */
            , <4  0 &gpioc 15 0>    /* PC15 */
            , <10 0 &gpioa 0  0>    /* PA0  */
            , <11 0 &gpioa 1  0>    /* PA1  */
            , <12 0 &gpioa 2  0>    /* PA2  */
            , <13 0 &gpioa 3  0>    /* PA3  */
            , <14 0 &gpioa 4  0>    /* PA4  */
            , <15 0 &gpioa 5  0>    /* PA5  */
            , <16 0 &gpioa 6  0>    /* PA6  */
            , <17 0 &gpioa 7  0>    /* PA7  */
            , <18 0 &gpiob 0  0>    /* PB0  */
            , <19 0 &gpiob 1  0>    /* PB1  */
            , <20 0 &gpiob 2  0>    /* PB2  */
            , <21 0 &gpiob 10 0>    /* PB10 */
            , <25 0 &gpiob 12 0>    /* PB12 */
            , <26 0 &gpiob 13 0>    /* PB13 */
            , <27 0 &gpiob 14 0>    /* PB14 */
            , <28 0 &gpiob 15 0>    /* PB15 */
            , <29 0 &gpioa 8  0>    /* PA8  */
            , <30 0 &gpioa 9  0>    /* PA9  */
            , <31 0 &gpioa 10 0>    /* PA10 */
            , <38 0 &gpioa 15 0>    /* PA15 */
            , <39 0 &gpiob 3  0>    /* PB3  */
            , <40 0 &gpiob 4  0>    /* PB4  */
            , <41 0 &gpiob 5  0>    /* PB5  */
            , <42 0 &gpiob 6  0>    /* PB6  */
            , <43 0 &gpiob 7  0>    /* PB7  */
            , <45 0 &gpiob 8  0>    /* PB8  */
            , <46 0 &gpiob 9  0>    /* PB9  */
            ;
    };
};

blackpill_i2c: &i2c1 {};
blackpill_spi: &spi1 {};
blackpill_serial: &usart1 {};

&blackpill_serial { status = "disabled"; };
```

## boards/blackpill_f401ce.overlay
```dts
/*
 * Copyright (c) 2022 The ZMK Contributors
 *
 * SPDX-License-Identifier: MIT
 */


/ {
    blackpill: connector {
        compatible = "blackpill";
        #gpio-cells = <2>;
        gpio-map-mask = <0xffffffff 0xffffffc0>;
        gpio-map-pass-thru = <0 0x3f>;
        gpio-map
            = <2  0 &gpioc 13 0>    /* PC13 */
            , <3  0 &gpioc 14 0>    /* PC14 */
            , <4  0 &gpioc 15 0>    /* PC15 */
            , <10 0 &gpioa 0  0>    /* PA0  */
            , <11 0 &gpioa 1  0>    /* PA1  */
            , <12 0 &gpioa 2  0>    /* PA2  */
            , <13 0 &gpioa 3  0>    /* PA3  */
            , <14 0 &gpioa 4  0>    /* PA4  */
            , <15 0 &gpioa 5  0>    /* PA5  */
            , <16 0 &gpioa 6  0>    /* PA6  */
            , <17 0 &gpioa 7  0>    /* PA7  */
            , <18 0 &gpiob 0  0>    /* PB0  */
            , <19 0 &gpiob 1  0>    /* PB1  */
            , <20 0 &gpiob 2  0>    /* PB2  */
            , <21 0 &gpiob 10 0>    /* PB10 */
            , <25 0 &gpiob 12 0>    /* PB12 */
            , <26 0 &gpiob 13 0>    /* PB13 */
            , <27 0 &gpiob 14 0>    /* PB14 */
            , <28 0 &gpiob 15 0>    /* PB15 */
            , <29 0 &gpioa 8  0>    /* PA8  */
            , <30 0 &gpioa 9  0>    /* PA9  */
            , <31 0 &gpioa 10 0>    /* PA10 */
            , <38 0 &gpioa 15 0>    /* PA15 */
            , <39 0 &gpiob 3  0>    /* PB3  */
            , <40 0 &gpiob 4  0>    /* PB4  */
            , <41 0 &gpiob 5  0>    /* PB5  */
            , <42 0 &gpiob 6  0>    /* PB6  */
            , <43 0 &gpiob 7  0>    /* PB7  */
            , <45 0 &gpiob 8  0>    /* PB8  */
            , <46 0 &gpiob 9  0>    /* PB9  */
            ;
    };
};

blackpill_i2c: &i2c1 {};
blackpill_spi: &spi1 {};
blackpill_serial: &usart1 {};

&blackpill_serial { status = "disabled"; };
```

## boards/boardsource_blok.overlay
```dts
/*
 * Copyright (c) 2023 The ZMK Contributors
 *
 * SPDX-License-Identifier: MIT
 */

#include "usb_console.dtsi"

&pro_micro_serial { status = "disabled"; };
```

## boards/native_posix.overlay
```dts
#include <behaviors.dtsi>
#include <dt-bindings/zmk/keys.h>
#include <dt-bindings/zmk/kscan_mock.h>

/ {
    chosen {
        zmk,kscan = &kscan;
    };

    kscan: kscan {
        compatible = "zmk,kscan-mock";

        rows = <2>;
        columns = <2>;
        exit-after;
    };
};
```

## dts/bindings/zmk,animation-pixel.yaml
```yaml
# Copyright (c) 2020, The ZMK Contributors
# SPDX-License-Identifier: MIT

description: Pixel configuration

compatible: "zmk,animation-pixel"

pixel-cells:
  - position_x
  - position_y
```

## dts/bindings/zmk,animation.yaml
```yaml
# Copyright (c) 2020, The ZMK Contributors
# SPDX-License-Identifier: MIT

description: Global animation configuration

compatible: "zmk,animation"

properties:
  drivers:
    type: phandles
    required: true
    description: |
      This array should contain all driver devices responsible for illuminating animated LEDs.
      The devices must implement Zephyr's LED Strip Interface.

  chain-lengths:
    type: array
    required: true
    description: |
      This field contains the number of LEDs controlled by each driver device.

  pixels:
    type: phandle-array
    required: true
    description: |
      This field contains the pixel configuration for the entire board.
      The order of this array determines in what order pixels are sent to the driver device API.
      If multiple driving devices are used, their chain-length property determines the size of the buffer for each device.

  key-pixels:
    type: array
    description: |
      Use this field to specify the pixel index corresponding to each key
      following the order used in your keymap.
      When left unspecified, the driver assumes that for every key, the pixel has a matching id.
      So for N keys, the first N pixels are exactly in the same order as keys in your keymap.
```

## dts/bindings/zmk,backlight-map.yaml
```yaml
description: |
  Allows defining a keymap composed of multiple layers

compatible: "zmk,backlight-map"

properties:
  led-channels:
    type: phandle-array
    required: true
```

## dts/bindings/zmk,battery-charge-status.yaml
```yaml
# Copyright (c) 2026 The ZMK Contributors
# SPDX-License-Identifier: MIT

description: |
  Reports whether the battery is charging, by reading the status output(s) of a
  battery charger IC.

  The charger ICs used on wireless keyboards expose one or two open drain status
  pins that are pulled low to signal a state, so they are normally described
  with GPIO_ACTIVE_LOW, and need a pull up if the board does not have one.

  A charger with a single status pin, such as the MCP73831, cannot distinguish
  "charge complete" from "no power applied":

      charge_status {
          compatible = "zmk,battery-charge-status";
          charging-gpios = <&gpio0 5 (GPIO_ACTIVE_LOW | GPIO_PULL_UP)>;
      };

  A charger with a separate charge complete output, such as the TP4056, can:

      charge_status {
          compatible = "zmk,battery-charge-status";
          charging-gpios = <&gpio0 5 (GPIO_ACTIVE_LOW | GPIO_PULL_UP)>;
          full-gpios = <&gpio0 6 (GPIO_ACTIVE_LOW | GPIO_PULL_UP)>;
      };

compatible: "zmk,battery-charge-status"

properties:
  charging-gpios:
    type: phandle-array
    required: true
    description: |
      Charge status output of the charger, asserted while the battery is
      charging. This is the STAT pin on a MCP73831, or the CHRG pin on a TP4056.

  full-gpios:
    type: phandle-array
    required: false
    description: |
      Charge complete output of the charger, asserted once charging has
      finished. This is the STDBY pin on a TP4056. Leave unset on chargers that
      do not have a separate charge complete output, in which case a battery
      that is not charging is reported as discharging.

  debounce-ms:
    type: int
    default: 100
    description: |
      Time to wait for the status pins to settle before reporting a change.
      Charger status outputs can toggle repeatedly as the charge current
      approaches the termination threshold.
```

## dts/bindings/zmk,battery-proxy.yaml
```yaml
# Copyright (c) 2025 The ZMK Contributors
# SPDX-License-Identifier: MIT

description: |
  Descriptions of each split battery of this keyboard.

compatible: "zmk,battery-proxy"

child-binding:
  description: "Battery on a split part of the keyboard"
  properties:
    display-name:
      type: string
      required: false
      description: |
        A human-readable name for this battery. Defaults to readable form of CPF.
    cpf:
      type: int
      required: false
      description: |
        Characteristic Presentation Format descriptor
        for battery reporting
    hidden:
      type: boolean
      required: false
      description: |
        Indicates if the battery charge level should be reported
```

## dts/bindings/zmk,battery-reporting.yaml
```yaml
# Copyright (c) 2025 The ZMK Contributors
# SPDX-License-Identifier: MIT

description: |
  Descriptions of each split battery of this keyboard.

compatible: "zmk,battery-reporting"

child-binding:
  description: "Battery on a split part of the keyboard"
  properties:
    display-name:
      type: string
      required: false
      description: |
        A human-readable name for this battery. Defaults to readable form of CPF.
    cpf:
      type: int
      required: false
      description: |
        Characteristic Presentation Format descriptor
        for battery reporting
    hidden:
      type: boolean
      required: false
      description: |
        Indicates if the battery charge level should be reported
```

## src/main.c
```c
/*
 * Copyright (c) 2020 The ZMK Contributors
 *
 * SPDX-License-Identifier: MIT
 */

#include <zephyr/kernel.h>
#include <zephyr/device.h>
#include <zephyr/devicetree.h>
#include <zephyr/settings/settings.h>

#include <zephyr/logging/log.h>
LOG_MODULE_REGISTER(zmk, CONFIG_ZMK_LOG_LEVEL);

#if IS_ENABLED(CONFIG_ZMK_DISPLAY)

#include <zmk/display.h>
#include <lvgl.h>

#endif

int main(void) {
    LOG_INF("Welcome to ZMK!\n");

#if IS_ENABLED(CONFIG_SETTINGS)
    settings_subsys_init();
    settings_load();
#endif

#ifdef CONFIG_ZMK_DISPLAY
    zmk_display_init();
#if IS_ENABLED(CONFIG_ARCH_POSIX)
    // Workaround for an SDL display issue:
    // https://github.com/zephyrproject-rtos/zephyr/issues/71410
    while (1) {
        lv_task_handler();
        k_sleep(K_MSEC(10));
    }
#endif

#endif /* CONFIG_ZMK_DISPLAY */

    return 0;
}
```

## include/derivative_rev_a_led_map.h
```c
/*
 * Derivative Rev A LED Map Configuration
 *
 * 51 LEDs total:
 *   0-2:   Indicators (caps lock, BT status, layer status)
 *   3-50:  Per-key (48 keys)
 *
 * Layout: 6 + 12 + 11 + 11 + 8 keys
 */

#pragma once

#define UNDERGLOW_COUNT 0
static const uint8_t underglow_map[UNDERGLOW_COUNT] = {};

#define PER_KEY_COUNT 48
static const uint8_t per_key_map[PER_KEY_COUNT] = {
    3,  4,  5,  6,  7,  8,                         /* Row 0: 6 keys  */
    20, 19, 18, 17, 16, 15, 14, 13, 12, 11, 10, 9, /* Row 1: 12 keys */
    21, 22, 23, 24, 25, 26, 27, 28, 29, 30, 31,    /* Row 2: 11 keys */
    42, 41, 40, 39, 38, 37, 36, 35, 34, 33, 32,    /* Row 3: 11 keys */
    43, 44, 45, 46, 47, 48, 49, 50                 /* Row 4: 8 keys  */
};

#define PER_KEY_ROW_COUNT 5
static const uint8_t per_key_row_sizes[PER_KEY_ROW_COUNT] = {6, 12, 11, 11, 8};

#define PER_KEY_COL_MAX 12
static const uint8_t per_key_col[PER_KEY_COUNT] = {
    0, 1, 2, 3, 4, 5,                     /* Row 0: 6 keys  */
    0, 1, 2, 3, 4, 5, 6, 7, 8, 9, 10, 11, /* Row 1: 12 keys */
    0, 1, 2, 3, 4, 5, 6, 7, 8, 9, 10,     /* Row 2: 11 keys */
    0, 1, 2, 3, 4, 5, 6, 7, 8, 9, 10,     /* Row 3: 11 keys */
    0, 1, 2, 3, 4, 5, 6, 7,               /* Row 4: 8 keys  */
};
```

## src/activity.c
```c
/*
 * Copyright (c) 2020 The ZMK Contributors
 *
 * SPDX-License-Identifier: MIT
 */

#include <zephyr/device.h>
#include <zephyr/init.h>
#include <zephyr/kernel.h>
#include <zephyr/sys/poweroff.h>

#include <zephyr/logging/log.h>

LOG_MODULE_DECLARE(zmk, CONFIG_ZMK_LOG_LEVEL);

#include <zmk/event_manager.h>
#include <zmk/events/activity_state_changed.h>
#include <zmk/events/position_state_changed.h>
#include <zmk/events/sensor_event.h>

#include <zmk/pm.h>

#include <zmk/activity.h>

#if IS_ENABLED(CONFIG_USB_DEVICE_STACK)
#include <zmk/usb.h>
#endif

#if IS_ENABLED(CONFIG_ZMK_POINTING)
#include <zephyr/input/input.h>
#endif

bool is_usb_power_present(void) {
#if IS_ENABLED(CONFIG_USB_DEVICE_STACK)
    return zmk_usb_is_powered();
#else
    return false;
#endif /* IS_ENABLED(CONFIG_USB_DEVICE_STACK) */
}

static enum zmk_activity_state activity_state;

static uint32_t activity_last_uptime;

#define MAX_IDLE_MS CONFIG_ZMK_IDLE_TIMEOUT

#if IS_ENABLED(CONFIG_ZMK_SLEEP)
#define MAX_SLEEP_MS CONFIG_ZMK_IDLE_SLEEP_TIMEOUT
#endif

int raise_event(void) {
    return raise_zmk_activity_state_changed(
        (struct zmk_activity_state_changed){.state = activity_state});
}

int set_state(enum zmk_activity_state state) {
    if (activity_state == state)
        return 0;

    activity_state = state;
    return raise_event();
}

#if IS_ENABLED(CONFIG_ZMK_TEST_BEHAVIORS)
int zmk_activity_test_set_state(enum zmk_activity_state state) {
    if (state == ZMK_ACTIVITY_ACTIVE) {
        activity_last_uptime = k_uptime_get();
    }

    activity_state = state;
    return raise_event();
}
#endif

enum zmk_activity_state zmk_activity_get_state(void) { return activity_state; }

static int note_activity(void) {
    activity_last_uptime = k_uptime_get();

    return set_state(ZMK_ACTIVITY_ACTIVE);
}

static int activity_event_listener(const zmk_event_t *eh) { return note_activity(); }

void activity_work_handler(struct k_work *work) {
    int32_t current = k_uptime_get();
    int32_t inactive_time = current - activity_last_uptime;
#if IS_ENABLED(CONFIG_ZMK_SLEEP)
    if (inactive_time > MAX_SLEEP_MS && !is_usb_power_present()) {
        // Put devices in suspend power mode before sleeping
        set_state(ZMK_ACTIVITY_SLEEP);

        if (zmk_pm_suspend_devices() < 0) {
            LOG_ERR("Failed to suspend all the devices");
            zmk_pm_resume_devices();
            return;
        }

        sys_poweroff();
    } else
#endif /* IS_ENABLED(CONFIG_ZMK_SLEEP) */
        if (inactive_time > MAX_IDLE_MS) {
            set_state(ZMK_ACTIVITY_IDLE);
        }
}

K_WORK_DEFINE(activity_work, activity_work_handler);

void activity_expiry_function(struct k_timer *_timer) { k_work_submit(&activity_work); }

K_TIMER_DEFINE(activity_timer, activity_expiry_function, NULL);

static int activity_init(void) {
    activity_last_uptime = k_uptime_get();

    k_timer_start(&activity_timer, K_SECONDS(1), K_SECONDS(1));
    return 0;
}

ZMK_LISTENER(activity, activity_event_listener);
ZMK_SUBSCRIPTION(activity, zmk_position_state_changed);
ZMK_SUBSCRIPTION(activity, zmk_sensor_event);

#if IS_ENABLED(CONFIG_ZMK_POINTING)

static void note_activity_work_cb(struct k_work *_work) { note_activity(); }

K_WORK_DEFINE(note_activity_work, note_activity_work_cb);

static void activity_input_listener(struct input_event *ev, void *user_data) {
    k_work_submit(&note_activity_work);
}

INPUT_CALLBACK_DEFINE(NULL, activity_input_listener, NULL);

#endif

SYS_INIT(activity_init, APPLICATION, CONFIG_APPLICATION_INIT_PRIORITY);
```
